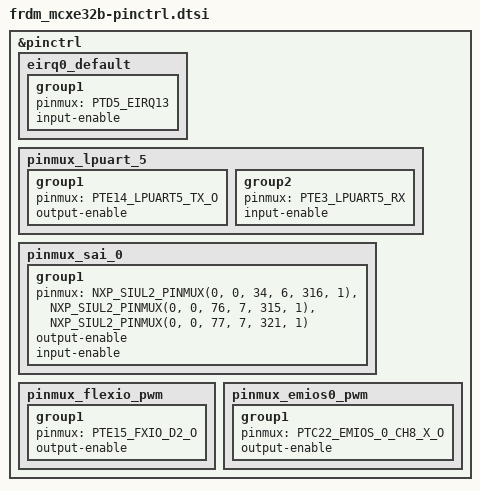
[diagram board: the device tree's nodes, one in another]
/*
 * SPDX-FileCopyrightText: Copyright 2026 NXP
 *
 * SPDX-License-Identifier: Apache-2.0
 */

#include <nxp/mcx/mcxe/pinctrl/MCXE32BMPB-pinctrl.h>

&pinctrl {
	eirq0_default: eirq0_default {
		group1 {
			pinmux = <PTD5_EIRQ13>;
			input-enable;
		};
	};

	pinmux_lpuart_5: pinmux_lpuart_5 {
		group1 {
			pinmux = <PTE14_LPUART5_TX_O>;
			output-enable;
		};

		group2 {
			pinmux = <PTE3_LPUART5_RX>;
			input-enable;
		};
	};

	pinmux_sai_0: pinmux_sai_0 {
		group1 {
			pinmux = <NXP_SIUL2_PINMUX(0, 0, 34, 6, 316, 1)>,
				 <NXP_SIUL2_PINMUX(0, 0, 76, 7, 315, 1)>,
				 <NXP_SIUL2_PINMUX(0, 0, 77, 7, 321, 1)>;
			output-enable;
			input-enable;
		};
	};

	pinmux_flexio_pwm: pinmux_flexio_pwm {
		group1 {
			pinmux = <PTE15_FXIO_D2_O>;
			output-enable;
		};
	};

	pinmux_emios0_pwm: pinmux_emios0_pwm {
		group1 {
			pinmux = <PTC22_EMIOS_0_CH8_X_O>;
			output-enable;
		};
	};
};
